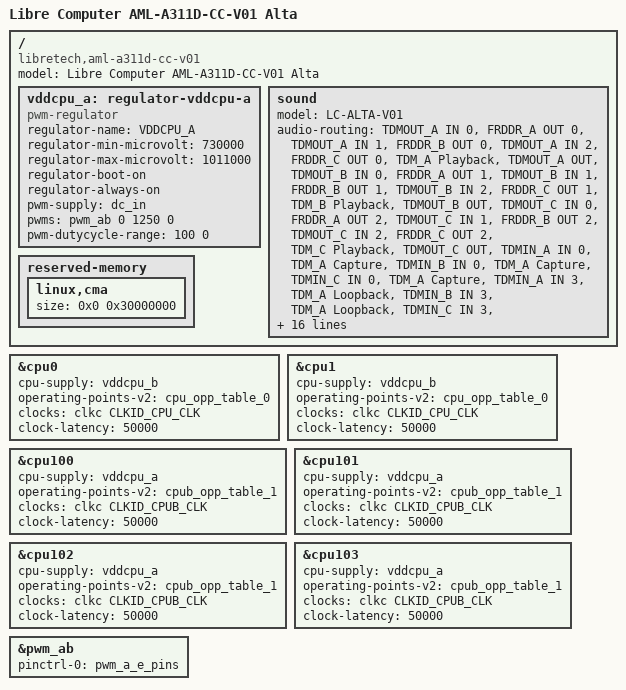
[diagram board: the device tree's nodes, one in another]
// SPDX-License-Identifier: (GPL-2.0+ OR MIT)
/*
 * Libre Computer AML-A311D-CC-V01 (Alta V0.1 pre-production)
 */

/dts-v1/;

#include <dt-bindings/clock/g12a-clkc.h>
#include "meson-g12b-a311d.dtsi"
#include "meson-libretech-cottonwood.dtsi"
#include "meson-libretech-cottonwood-v01.dtsi"
#include "meson-g12-vendor-firmware.dtsi"
#include "meson-libretech-ramoops.dtsi"

/ {
	compatible = "libretech,aml-a311d-cc-v01", "amlogic,a311d", "amlogic,g12b";
	model = "Libre Computer AML-A311D-CC-V01 Alta";

	vddcpu_a: regulator-vddcpu-a {
		compatible = "pwm-regulator";
		regulator-name = "VDDCPU_A";
		regulator-min-microvolt = <730000>;
		regulator-max-microvolt = <1011000>;
		regulator-boot-on;
		regulator-always-on;
		pwm-supply = <&dc_in>;
		pwms = <&pwm_ab 0 1250 0>;
		pwm-dutycycle-range = <100 0>;
	};

	sound {
		model = "LC-ALTA-V01";
		audio-routing = "TDMOUT_A IN 0", "FRDDR_A OUT 0",
				"TDMOUT_A IN 1", "FRDDR_B OUT 0",
				"TDMOUT_A IN 2", "FRDDR_C OUT 0",
				"TDM_A Playback", "TDMOUT_A OUT",
				"TDMOUT_B IN 0", "FRDDR_A OUT 1",
				"TDMOUT_B IN 1", "FRDDR_B OUT 1",
				"TDMOUT_B IN 2", "FRDDR_C OUT 1",
				"TDM_B Playback", "TDMOUT_B OUT",
				"TDMOUT_C IN 0", "FRDDR_A OUT 2",
				"TDMOUT_C IN 1", "FRDDR_B OUT 2",
				"TDMOUT_C IN 2", "FRDDR_C OUT 2",
				"TDM_C Playback", "TDMOUT_C OUT",
				"TDMIN_A IN 0", "TDM_A Capture",
				"TDMIN_B IN 0", "TDM_A Capture",
				"TDMIN_C IN 0", "TDM_A Capture",
				"TDMIN_A IN 3", "TDM_A Loopback",
				"TDMIN_B IN 3", "TDM_A Loopback",
				"TDMIN_C IN 3", "TDM_A Loopback",
				"TDMIN_A IN 1", "TDM_B Capture",
				"TDMIN_B IN 1", "TDM_B Capture",
				"TDMIN_C IN 1", "TDM_B Capture",
				"TDMIN_A IN 4", "TDM_B Loopback",
				"TDMIN_B IN 4", "TDM_B Loopback",
				"TDMIN_C IN 4", "TDM_B Loopback",
				"TDMIN_A IN 2", "TDM_C Capture",
				"TDMIN_B IN 2", "TDM_C Capture",
				"TDMIN_C IN 2", "TDM_C Capture",
				"TDMIN_A IN 5", "TDM_C Loopback",
				"TDMIN_B IN 5", "TDM_C Loopback",
				"TDMIN_C IN 5", "TDM_C Loopback",
				"TODDR_A IN 0", "TDMIN_A OUT",
				"TODDR_B IN 0", "TDMIN_A OUT",
				"TODDR_C IN 0", "TDMIN_A OUT",
				"TODDR_A IN 1", "TDMIN_B OUT",
				"TODDR_B IN 1", "TDMIN_B OUT",
				"TODDR_C IN 1", "TDMIN_B OUT",
				"TODDR_A IN 2", "TDMIN_C OUT",
				"TODDR_B IN 2", "TDMIN_C OUT",
				"TODDR_C IN 2", "TDMIN_C OUT",
				"Lineout", "ACODEC LOLP",
				"Lineout", "ACODEC LORP";
	};
};

&cpu0 {
	cpu-supply = <&vddcpu_b>;
	operating-points-v2 = <&cpu_opp_table_0>;
	clocks = <&clkc CLKID_CPU_CLK>;
	clock-latency = <50000>;
};

&cpu1 {
	cpu-supply = <&vddcpu_b>;
	operating-points-v2 = <&cpu_opp_table_0>;
	clocks = <&clkc CLKID_CPU_CLK>;
	clock-latency = <50000>;
};

&cpu100 {
	cpu-supply = <&vddcpu_a>;
	operating-points-v2 = <&cpub_opp_table_1>;
	clocks = <&clkc CLKID_CPUB_CLK>;
	clock-latency = <50000>;
};

&cpu101 {
	cpu-supply = <&vddcpu_a>;
	operating-points-v2 = <&cpub_opp_table_1>;
	clocks = <&clkc CLKID_CPUB_CLK>;
	clock-latency = <50000>;
};

&cpu102 {
	cpu-supply = <&vddcpu_a>;
	operating-points-v2 = <&cpub_opp_table_1>;
	clocks = <&clkc CLKID_CPUB_CLK>;
	clock-latency = <50000>;
};

&cpu103 {
	cpu-supply = <&vddcpu_a>;
	operating-points-v2 = <&cpub_opp_table_1>;
	clocks = <&clkc CLKID_CPUB_CLK>;
	clock-latency = <50000>;
};


/*
 * V01: pwm_ab only has ch0 (PWM_A / GPIOE_2) for VDDCPU_A, no ch1 for the
 * blue LED. PWM_A is the A73 cluster supply -- NOT an LED. Do not disable:
 * cpufreq-dt walks every present CPU before registering, so losing this rail
 * disables cpufreq on BOTH clusters.
 */
&pwm_ab {
	status = "okay";
	pinctrl-0 = <&pwm_a_e_pins>;
	pinctrl-names = "default";
};

/ {
	reserved-memory {
		linux,cma {
			/*
			 * AML-A311D-CC-V01 comes in up to 4 GiB RAM variants.
			 * U-Boot's meson_fixup_cma_size() writes min(this
			 * value, 7/32 of detected RAM) here and forces
			 * alloc-ranges to the first 1 GiB, so this value is the
			 * binding clamp whenever it is the smaller term.
			 *
			 * 768 MiB, not the 896 MiB the 7/32 formula yields at
			 * 4 GiB: the sub-1 GiB window is not 1 GiB wide.
			 * secmon, ramoops and the kernel image leave ~820 MiB
			 * of largest free run below 0x40000000, and 896 MiB was
			 * measured failing on both A311D and S905D3. A failed
			 * reservation costs the whole pool -- one pr_err, then
			 * CONFIG_CMA_SIZE_MBYTES=128 -- so over-asking loses
			 * 640 MiB rather than gaining 128.
			 */
			size = <0x0 0x30000000>;
		};
	};
};
